AUTOSAR XML (schema 4-0-3)
package /Svc_ComM
  data type mapping set ComMModeDataTypeMappingSet: mode-request-type-map{implementation-data-type=ComM_ModeType, mode-group=ComMMode}
  10 x impl type:
    ComM_ModeType: category=VALUE, base-type=uint8
    ComM_PncModeType: category=VALUE, base-type=uint8
    ComM_InhibitionStatusType: category=VALUE, base-type=uint8
    ComM_StateType: category=VALUE, base-type=uint8
    ComM_UserHandleArrayType: category=STRUCTURE
      element numberOfRequesters: category=VALUE, base-type=uint8
      element handleArray: category=ARRAY
        element handleArrayElement: array-size=2, array-size-semantics=FIXED-SIZE, implementation-data-type=ComM_UserHandleType
    ComM_UserHandleType: category=VALUE, base-type=uint8
    NetworkHandleType: category=VALUE, base-type=uint8, type-emitter=ComM
    PNCHandleType: category=VALUE, base-type=uint8, type-emitter=ComM
    ComM_BusMsgType: category=STRUCTURE
      element usTxMsgCnt: category=VALUE, base-type=uint32
      element usRxMsgCnt: category=VALUE, base-type=uint32
    ComM_InitStatusType: category=VALUE, base-type=uint8
  mode declaration group ComMMode: category=EXPLICIT_ORDER, initial-mode=COMM_NO_COMMUNICATION, on-transition-value=255
    mode COMM_NO_COMMUNICATION: category=EXPLICIT_ORDER, value=0
    mode COMM_SILENT_COMMUNICATION: category=EXPLICIT_ORDER, value=1
    mode COMM_FULL_COMMUNICATION: category=EXPLICIT_ORDER, value=2
  mode switch interface ComM_CurrentMode: is-service=true, service-kind=COM-MANAGER
    mode group currentMode: type=ComMMode
  sender receiver interface ComM_CurrentChannelRequest: is-service=true, service-kind=COM-MANAGER
    data fullComRequestors: type=ComM_UserHandleArrayType
  4 x client server interface, all with is-service=true, service-kind=COM-MANAGER:
    ComM_UserRequest
      operation RequestComMode: possible-error=[ComM_UserRequest/E_NOT_OK, E_MODE_LIMITATION]
        arg ComMode: type=ComM_ModeType, direction=IN
      operation GetCurrentComMode: possible-error=ComM_UserRequest/E_NOT_OK
        arg ComMode: type=ComM_ModeType, direction=OUT
      operation GetRequestedComMode: possible-error=ComM_UserRequest/E_NOT_OK
        arg ComMode: type=ComM_ModeType, direction=OUT
      error E_NOT_OK: error-code=1
      error E_MODE_LIMITATION: error-code=2
    ComM_ECUModeLimitation
      5 x operation, all with possible-error=ComM_ECUModeLimitation/E_NOT_OK:
        GetStatus
          arg Status: type=ComM_InitStatusType, direction=OUT
        LimitECUToNoComMode
          arg Status: type=boolean, direction=IN
        ReadInhibitCounter
          arg CounterValue: type=uint16, direction=OUT
        ResetInhibitCounter
        SetECUGroupClassification
          arg Status: type=ComM_InhibitionStatusType, direction=IN
      error E_NOT_OK: error-code=1
    ComM_ChannelLimitation
      4 x operation, all with possible-error=ComM_ChannelLimitation/E_NOT_OK:
        LimitChannelToNoComMode
          arg Status: type=boolean, direction=IN
        PreventWakeUp
          arg Status: type=boolean, direction=IN
        GetState
          arg State: type=ComM_StateType, direction=OUT
        GetInhibitionStatus
          arg Status: type=ComM_InhibitionStatusType, direction=OUT
      error E_NOT_OK: error-code=1
    ComM_GetChannelBusLoad
      operation GetChannelBusLoad: possible-error=ComM_GetChannelBusLoad/E_NOT_OK
        arg Channel: type=uint8, direction=IN
        arg BusLoad: type=ComM_BusMsgType, direction=OUT
      error E_NOT_OK: error-code=1
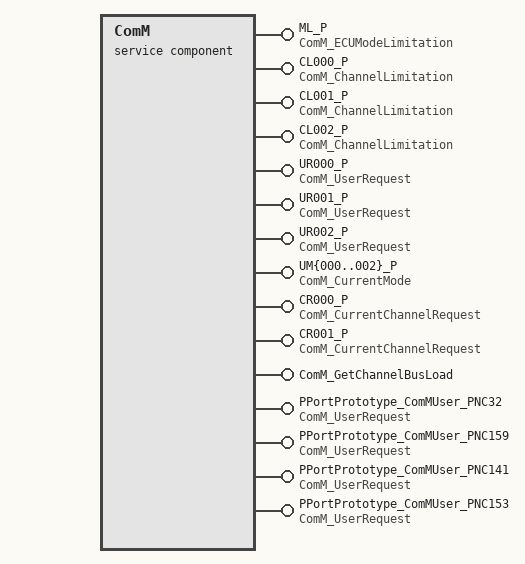
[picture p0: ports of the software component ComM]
  service sw component type ComM
    17 x provide port:
      ML_P: provided-interface=ComM_ECUModeLimitation
        provided-com-specs:
          operation=GetStatus, queue-length=1
          operation=LimitECUToNoComMode, queue-length=1
          operation=ReadInhibitCounter, queue-length=1
          operation=ResetInhibitCounter, queue-length=1
          operation=SetECUGroupClassification, queue-length=1
      CL000_P: provided-interface=ComM_ChannelLimitation
        provided-com-specs:
          operation=LimitChannelToNoComMode, queue-length=1
          operation=PreventWakeUp, queue-length=1
          operation=GetState, queue-length=1
          operation=GetInhibitionStatus, queue-length=1
      CL001_P: provided-interface=ComM_ChannelLimitation
        provided-com-specs:
          operation=LimitChannelToNoComMode, queue-length=1
          operation=PreventWakeUp, queue-length=1
          operation=GetState, queue-length=1
          operation=GetInhibitionStatus, queue-length=1
      CL002_P: provided-interface=ComM_ChannelLimitation
        provided-com-specs:
          operation=LimitChannelToNoComMode, queue-length=1
          operation=PreventWakeUp, queue-length=1
          operation=GetState, queue-length=1
          operation=GetInhibitionStatus, queue-length=1
      UR000_P: provided-interface=ComM_UserRequest
        provided-com-specs:
          operation=RequestComMode, queue-length=1
          operation=GetCurrentComMode, queue-length=1
          operation=GetRequestedComMode, queue-length=1
      UR001_P: provided-interface=ComM_UserRequest
        provided-com-specs:
          operation=RequestComMode, queue-length=1
          operation=GetCurrentComMode, queue-length=1
          operation=GetRequestedComMode, queue-length=1
      UR002_P: provided-interface=ComM_UserRequest
        provided-com-specs:
          operation=RequestComMode, queue-length=1
          operation=GetCurrentComMode, queue-length=1
          operation=GetRequestedComMode, queue-length=1
      UM{000..002}_P: mode-switch-sender-com-spec{enhanced-mode-api=false, mode-group=currentMode, queue-length=1}, provided-interface=ComM_CurrentMode
      CR000_P: nonqueued-sender-com-spec=fullComRequestors, provided-interface=ComM_CurrentChannelRequest
      CR001_P: nonqueued-sender-com-spec=fullComRequestors, provided-interface=ComM_CurrentChannelRequest
      ComM_GetChannelBusLoad: server-com-spec{operation=GetChannelBusLoad, queue-length=1}, provided-interface=ComM_GetChannelBusLoad
      PPortPrototype_ComMUser_PNC32: provided-interface=ComM_UserRequest
        provided-com-specs:
          operation=RequestComMode, queue-length=1
          operation=GetCurrentComMode, queue-length=1
          operation=GetRequestedComMode, queue-length=1
      PPortPrototype_ComMUser_PNC159: provided-interface=ComM_UserRequest
        provided-com-specs:
          operation=RequestComMode, queue-length=1
          operation=GetCurrentComMode, queue-length=1
          operation=GetRequestedComMode, queue-length=1
      PPortPrototype_ComMUser_PNC141: provided-interface=ComM_UserRequest
        provided-com-specs:
          operation=RequestComMode, queue-length=1
          operation=GetCurrentComMode, queue-length=1
          operation=GetRequestedComMode, queue-length=1
      PPortPrototype_ComMUser_PNC153: provided-interface=ComM_UserRequest
        provided-com-specs:
          operation=RequestComMode, queue-length=1
          operation=GetCurrentComMode, queue-length=1
          operation=GetRequestedComMode, queue-length=1
    behavior SwcIB_ComM
      39 x operation invoked event:
        OIE_GetStatus_ML: start-on-event=GetStatus, operation=ML_P.GetStatus
        OIE_LimitECUToNoComMode_ML: start-on-event=LimitECUToNoComMode, operation=ML_P.LimitECUToNoComMode
        OIE_ReadInhibitCounter_ML: start-on-event=ReadInhibitCounter, operation=ML_P.ReadInhibitCounter
        OIE_ResetInhibitCounter_ML: start-on-event=ResetInhibitCounter, operation=ML_P.ResetInhibitCounter
        OIE_SetECUGroupClassification_ML: start-on-event=SetECUGroupClassification, operation=ML_P.SetECUGroupClassification
        OIE_LimitChannelToNoComMode_CL000: start-on-event=LimitChannelToNoComMode, operation=CL000_P.LimitChannelToNoComMode
        OIE_PreventWakeUp_CL000: start-on-event=PreventWakeup, operation=CL000_P.PreventWakeUp
        OIE_GetState_CL000: start-on-event=GetState, operation=CL000_P.GetState
        OIE_GetInhibitionStatus_CL000: start-on-event=GetInhibitionStatus, operation=CL000_P.GetInhibitionStatus
        OIE_LimitChannelToNoComMode_CL001: start-on-event=LimitChannelToNoComMode, operation=CL001_P.LimitChannelToNoComMode
        OIE_PreventWakeUp_CL001: start-on-event=PreventWakeup, operation=CL001_P.PreventWakeUp
        OIE_GetState_CL001: start-on-event=GetState, operation=CL001_P.GetState
        OIE_GetInhibitionStatus_CL001: start-on-event=GetInhibitionStatus, operation=CL001_P.GetInhibitionStatus
        OIE_LimitChannelToNoComMode_CL002: start-on-event=LimitChannelToNoComMode, operation=CL002_P.LimitChannelToNoComMode
        OIE_PreventWakeUp_CL002: start-on-event=PreventWakeup, operation=CL002_P.PreventWakeUp
        OIE_GetState_CL002: start-on-event=GetState, operation=CL002_P.GetState
        OIE_GetInhibitionStatus_CL002: start-on-event=GetInhibitionStatus, operation=CL002_P.GetInhibitionStatus
        OIE_RequestComMode_UR000: start-on-event=RequestComMode, operation=UR000_P.RequestComMode
        OIE_GetCurrentComMode_UR000: start-on-event=GetCurrentComMode, operation=UR000_P.GetCurrentComMode
        OIE_GetRequestedComMode_UR000: start-on-event=GetRequestedComMode, operation=UR000_P.GetRequestedComMode
        OIE_RequestComMode_UR001: start-on-event=RequestComMode, operation=UR001_P.RequestComMode
        OIE_GetCurrentComMode_UR001: start-on-event=GetCurrentComMode, operation=UR001_P.GetCurrentComMode
        OIE_GetRequestedComMode_UR001: start-on-event=GetRequestedComMode, operation=UR001_P.GetRequestedComMode
        OIE_RequestComMode_UR002: start-on-event=RequestComMode, operation=UR002_P.RequestComMode
        OIE_GetCurrentComMode_UR002: start-on-event=GetCurrentComMode, operation=UR002_P.GetCurrentComMode
        OIE_GetRequestedComMode_UR002: start-on-event=GetRequestedComMode, operation=UR002_P.GetRequestedComMode
        OIE_ComM_GetChannelBusLoad_ComM_GetChannelBusLoad_GetChannelBusLoad: start-on-event=GetChannelBusLoad, operation=ComM_GetChannelBusLoad.GetChannelBusLoad
        OperationInvokedEvent_RequestComMode_ComMUser_PNC32: start-on-event=RequestComMode, operation=PPortPrototype_ComMUser_PNC32.RequestComMode
        OperationInvokedEvent_GetCurrentComMode_ComMUser_PNC32: start-on-event=GetCurrentComMode, operation=PPortPrototype_ComMUser_PNC32.GetCurrentComMode
        OperationInvokedEvent_GetRequestedComMode_ComMUser_PNC32: start-on-event=GetRequestedComMode, operation=PPortPrototype_ComMUser_PNC32.GetRequestedComMode
        OperationInvokedEvent_RequestComMode_ComMUser_PNC159: start-on-event=RequestComMode, operation=PPortPrototype_ComMUser_PNC159.RequestComMode
        OperationInvokedEvent_GetCurrentComMode_ComMUser_PNC159: start-on-event=GetCurrentComMode, operation=PPortPrototype_ComMUser_PNC159.GetCurrentComMode
        OperationInvokedEvent_GetRequestedComMode_ComMUser_PNC159: start-on-event=GetRequestedComMode, operation=PPortPrototype_ComMUser_PNC159.GetRequestedComMode
        OperationInvokedEvent_RequestComMode_ComMUser_PNC141: start-on-event=RequestComMode, operation=PPortPrototype_ComMUser_PNC141.RequestComMode
        OperationInvokedEvent_GetCurrentComMode_ComMUser_PNC141: start-on-event=GetCurrentComMode, operation=PPortPrototype_ComMUser_PNC141.GetCurrentComMode
        OperationInvokedEvent_GetRequestedComMode_ComMUser_PNC141: start-on-event=GetRequestedComMode, operation=PPortPrototype_ComMUser_PNC141.GetRequestedComMode
        OperationInvokedEvent_RequestComMode_ComMUser_PNC153: start-on-event=RequestComMode, operation=PPortPrototype_ComMUser_PNC153.RequestComMode
        OperationInvokedEvent_GetCurrentComMode_ComMUser_PNC153: start-on-event=GetCurrentComMode, operation=PPortPrototype_ComMUser_PNC153.GetCurrentComMode
        OperationInvokedEvent_GetRequestedComMode_ComMUser_PNC153: start-on-event=GetRequestedComMode, operation=PPortPrototype_ComMUser_PNC153.GetRequestedComMode
      port-api-options:
        {enable-take-address=true, indirect-api=false, port-defined-argument-value{value=0, value-type=NetworkHandleType}, port=CL000_P}
        {enable-take-address=true, indirect-api=false, port-defined-argument-value{value=1, value-type=NetworkHandleType}, port=CL001_P}
        {enable-take-address=true, indirect-api=false, port-defined-argument-value{value=2, value-type=NetworkHandleType}, port=CL002_P}
        {enable-take-address=true, indirect-api=false, port-defined-argument-value{value=0, value-type=ComM_UserHandleType}, port=UR000_P}
        {enable-take-address=true, indirect-api=false, port-defined-argument-value{value=1, value-type=ComM_UserHandleType}, port=UR001_P}
        {enable-take-address=true, indirect-api=false, port-defined-argument-value{value=2, value-type=ComM_UserHandleType}, port=UR002_P}
        enable-take-address=true, indirect-api=false, port=UM{000..002}_P
        {enable-take-address=true, indirect-api=false, port-defined-argument-value{value=0, value-type=ComM_UserHandleType}, port=PPortPrototype_ComMUser_PNC32}
        {enable-take-address=true, indirect-api=false, port-defined-argument-value{value=1, value-type=ComM_UserHandleType}, port=PPortPrototype_ComMUser_PNC159}
        {enable-take-address=true, indirect-api=false, port-defined-argument-value{value=2, value-type=ComM_UserHandleType}, port=PPortPrototype_ComMUser_PNC141}
        {enable-take-address=true, indirect-api=false, port-defined-argument-value{value=3, value-type=ComM_UserHandleType}, port=PPortPrototype_ComMUser_PNC153}
      13 x runnable:
        GetState: symbol=ComM_GetState
        GetStatus: symbol=ComM_GetStatus
        GetInhibitionStatus: symbol=ComM_GetInhibitionStatus
        RequestComMode: arguments=[symbol=User, symbol=ComMode], can-be-invoked-concurrently=true, symbol=ComM_RequestComMode
        GetRequestedComMode: arguments=[symbol=User, symbol=ComMode], can-be-invoked-concurrently=true, symbol=ComM_GetRequestedComMode
        GetCurrentComMode: arguments=[symbol=User, symbol=ComMode], can-be-invoked-concurrently=true, symbol=ComM_GetCurrentComMode
          data-send-points:
            access VariableAccess_0: accessed-variable=CR000_P.fullComRequestors, scope=COMMUNICATION-INTER-ECU
            access VariableAccess_1: accessed-variable=CR001_P.fullComRequestors, scope=COMMUNICATION-INTER-ECU
          mode switch point ModeSwitchPoint_CurrentMode_UM{000..002}: mode-group=UM{000..002}_P.currentMode
        PreventWakeup: symbol=ComM_PreventWakeUp
        LimitChannelToNoComMode: symbol=ComM_LimitChannelToNoComMode
        LimitECUToNoComMode: symbol=ComM_LimitECUToNoComMode
        ReadInhibitCounter: symbol=ComM_ReadInhibitCounter
        ResetInhibitCounter: symbol=ComM_ResetInhibitCounter
        SetECUGroupClassification: symbol=ComM_SetECUGroupClassification
        GetChannelBusLoad: can-be-invoked-concurrently=true, symbol=ComM_GetChannelBusLoad
  swc implementation SwcImplementation_ComM: swc-bsw-mapping=SwcBswMapping_ComM, behavior=SwcIB_ComM
